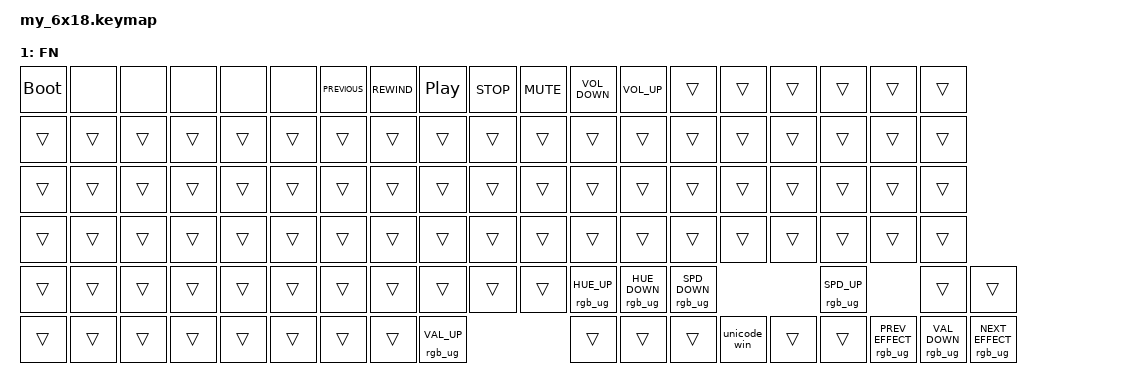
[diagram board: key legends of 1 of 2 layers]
#include <behaviors.dtsi>
#include <dt-bindings/zmk/keys.h>
#include <dt-bindings/zmk/bt.h>
#include <dt-bindings/zmk/outputs.h>

#define BASE 0
#define FN   1

/ {
    keymap {
        compatible = "zmk,keymap";

        base_layer {
            label = "BASE";
            bindings = <
                &kp ESC    &kp F1     &kp F2     &kp F3     &kp F4     &kp F5     &kp F6     &kp F7     &kp F8     &kp F9     &kp F10    &kp F11    &kp F12    &kp PSCR   &kp DEL    &kp INS    &kp PG_UP  &kp PG_DN
                &kp GRAVE  &kp N1     &kp N2     &kp N3     &kp N4     &kp N5     &kp N6     &kp N7     &kp N8     &kp N9     &kp N0     &kp MINUS  &kp EQUAL  &kp BSPC   &kp NUM    &kp KP_SLASH &kp KP_MULTIPLY &kp KP_MINUS
                &kp TAB    &kp Q      &kp W      &kp E      &kp R      &kp T      &kp Y      &kp U      &kp I      &kp O      &kp P      &kp LBKT   &kp RBKT   &kp BSLH   &kp KP_7   &kp KP_8   &kp KP_9   &kp KP_PLUS
                &kp CAPS   &kp A      &kp S      &kp D      &kp F      &kp G      &kp H      &kp J      &kp K      &kp L      &kp SEMI   &kp SQT    &kp RET    &kp KP_4   &kp KP_5   &kp KP_6   &trans     &trans
                &kp LSFT   &kp Z      &kp X      &kp C      &kp V      &kp B      &kp N      &kp M      &kp COMMA  &kp DOT    &kp FSLH   &kp RSFT   &kp UP     &kp KP_1   &kp KP_2   &kp KP_3   &kp KP_ENTER &trans
                &kp LCTRL  &kp LGUI   &kp LALT   &kp SPACE  &kp RALT   &mo FN     &kp RCTRL  &kp LEFT   &kp DOWN   &kp RIGHT  &kp KP_0   &kp KP_DOT &trans     &trans     &trans     &trans     &trans     &trans
            >;
        };

        fn_layer {
            label = "FN";
            bindings = <
                &bootloader  &none       &none       &none       &none       &none         &kp C_PREVIOUS &kp C_REWIND &kp C_PLAY_PAUSE &kp C_STOP    &kp C_MUTE   &kp C_VOLUME_DOWN &kp C_VOLUME_UP &trans &trans &trans &trans &trans &trans
                &trans       &trans      &trans      &trans      &trans      &trans        &trans         &trans       &trans           &trans        &trans       &trans             &trans          &trans &trans &trans &trans &trans &trans
                &trans       &trans      &trans      &trans      &trans      &trans        &trans         &trans       &trans           &trans        &trans       &trans             &trans          &trans &trans &trans &trans &trans &trans
                &trans       &trans      &trans      &trans      &trans      &trans        &trans         &trans       &trans           &trans        &trans       &trans             &trans          &trans &trans &trans &trans &trans &trans
                &trans       &trans      &trans      &trans      &trans      &trans        &trans         &trans       &trans           &trans        &trans       &rgb_ug HUE_UP     &rgb_ug HUE_DOWN &rgb_ug SPD_DOWN &rgb_ug SPD_UP &trans &trans
                &trans       &trans      &trans      &trans      &trans      &trans        &trans         &trans       &rgb_ug VAL_UP   &trans        &trans       &trans             &unicode_win    &trans &trans &rgb_ug PREV_EFFECT &rgb_ug VAL_DOWN &rgb_ug NEXT_EFFECT
            >;
        };
    };
};
